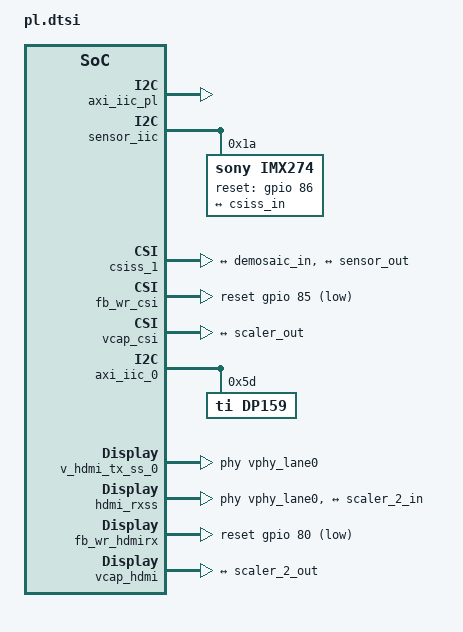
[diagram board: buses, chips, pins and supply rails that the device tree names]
/*
 * CAUTION: This file is automatically generated by Xilinx.
 * Version:  
 * Today is: Wed Nov  8 10:41:27 2017
 */


/ {
	amba_pl: amba_pl@0 {
		#address-cells = <2>;
		#size-cells = <2>;
		compatible = "simple-bus";
		ranges;
		
		psu_ctrl_ipi: PERIPHERAL@ff380000 {
			compatible = "xlnx,PERIPHERAL-1.0";
			reg = <0x0 0xff380000 0x0 0x80000>;
		};
		
		psu_message_buffers: PERIPHERAL@ff990000 {
			compatible = "xlnx,PERIPHERAL-1.0";
			reg = <0x0 0xff990000 0x0 0x10000>;
		};
		
		wl18xx_ctrl: gpio@a0002000 {
			#gpio-cells = <2>;
			compatible = "xlnx,xps-gpio-1.00.a";
			gpio-controller ;
			reg = <0x0 0xa0002000 0x0 0x1000>;
			xlnx,all-inputs = <0x0>;
			xlnx,all-inputs-2 = <0x0>;
			xlnx,all-outputs = <0x1>;
			xlnx,all-outputs-2 = <0x0>;
			xlnx,dout-default = <0x00000000>;
			xlnx,dout-default-2 = <0x00000000>;
			xlnx,gpio-width = <0x2>;
			xlnx,gpio2-width = <0x20>;
			xlnx,interrupt-present = <0x0>;
			xlnx,is-dual = <0x0>;
			xlnx,tri-default = <0xFFFFFFFF>;
			xlnx,tri-default-2 = <0xFFFFFFFF>;
		};
		
		misc_clk_0: misc_clk_0 {
			#clock-cells = <0>;
			clock-frequency = <50000000>;
			compatible = "fixed-clock";
		};
		
		misc_clk_1: misc_clk_1 {
			#clock-cells = <0>;
			clock-frequency = <300000000>;
			compatible = "fixed-clock";
		};
		
		axi_iic_pl: i2c@a0003000 {
			#address-cells = <1>;
			#size-cells = <0>;
			clocks = <&misc_clk_0>;
			compatible = "xlnx,xps-iic-2.00.a";
			interrupt-parent = <&axi_intc_0>;
			interrupts = <0 2>;
			reg = <0x0 0xa0003000 0x0 0x1000>;
		};
		
		axi_intc_0: interrupt-controller@a000a000 {
			#interrupt-cells = <2>;
			compatible = "xlnx,xps-intc-1.00.a";
			interrupt-controller ;
			interrupt-parent = <&gic>;
			interrupts = <0 89 4>;
			reg = <0x0 0xa000a000 0x0 0x1000>;
			xlnx,kind-of-intr = <0x0>;
			xlnx,num-intr-inputs = <0xa>;
		};
		
		/* MIPI CSI-2 SS */
		
		sensor_iic: i2c@a0080000 {
			#address-cells = <1>;
			#size-cells = <0>;
			clocks = <&misc_clk_0>;
			compatible = "xlnx,xps-iic-2.00.a";
			interrupt-parent = <&axi_intc_0>;
			interrupts = <9 2>;
			reg = <0x0 0xa0080000 0x0 0x10000>;
			
			imx274: sensor@1a {
				compatible = "sony,imx274";
				reg = <0x1a>;
				#address-cells = <1>;
				#size-cells = <0>;
				reset-gpios = <&gpio 86 0>;

				port@0 {
					reg = <0>;

					sensor_out: endpoint {
						remote-endpoint = <&csiss_in>;
					};
				};
			};
		};
		
		csiss_1: csiss@a0040000 {
			compatible = "xlnx,mipi-csi2-rx-subsystem-2.2", "xlnx,mipi-csi2-rx-subsystem-2.0", "xlnx,mipi-csi2-rx-subsystem";
			reg = <0x0 0xa0040000 0x0 0x10000>;
			clocks = <&misc_clk_1>;
			interrupt-parent = <&axi_intc_0>;
			interrupts = <7 2>;

			xlnx,max-lanes = <0x4>;
			xlnx,en-active-lanes;
			xlnx,vc = <0x4>;
			xlnx,csi-pxl-format = "RAW8";
			xlnx,vfb;
			xlnx,ppc = <0x4>;
			xlnx,axis-tdata-width = <0x20>;

			ports {
				#address-cells = <1>;
				#size-cells = <0>;

				port@0 {
					reg = <0>;

					xlnx,video-format = <12>;
					xlnx,video-width = <8>;
					xlnx,cfa-pattern = "rggb";

					csiss_out: endpoint {
						remote-endpoint = <&demosaic_in>;
					};
				};
				port@1 {
					reg = <1>;

					xlnx,video-format = <12>;
					xlnx,video-width = <8>;
					xlnx,cfa-pattern = "rggb";

					csiss_in: endpoint {
						data-lanes = <1 2 3 4>;
						remote-endpoint = <&sensor_out>;
					};
				};
			};
		};
		
		v_demosaic_0: v_demosaic@b0060000 {
			compatible = "xlnx,v-demosaic-v1.0", "xlnx,v-demosaic";
			reg = <0x0 0xb0060000 0x0 0x10000>;
			clocks = <&misc_clk_1>;

			reset-gpios = <&gpio 81 1>;

			ports {
				#address-cells = <1>;
				#size-cells = <0>;

				port@0 {
					reg = <0>;

					xlnx,video-width = <8>;
					xlnx,cfa-pattern = "rggb";

					demosaic_in: endpoint {
						remote-endpoint = <&csiss_out>;
					};
				};

				port@1 {
					reg = <1>;

					xlnx,video-width = <8>;

					demosaic_out: endpoint {
						remote-endpoint = <&gamma_in>;
					};
				};
			};
		};
		
		gamma_1: v_gamma@b0070000 {
			compatible = "xlnx,v-gamma-lut-1.0", "xlnx,v-gamma-lut-v1.0", "xlnx,v-gamma-lut";
			reg = <0x0 0xb0070000 0x0 0x10000>;
			clocks = <&misc_clk_1>;

			reset-gpios = <&gpio 82 1>;

			ports {
				#address-cells = <1>;
				#size-cells = <0>;

				port@0 {
					reg = <0>;

					xlnx,video-width = <8>;

					gamma_in: endpoint {
						remote-endpoint = <&demosaic_out>;
					};
				};

				port@1 {
					reg = <1>;

					xlnx,video-width = <8>;

					gamma_out: endpoint {
						remote-endpoint = <&csc_in>;
					};
				};
			};
		};
		
		csc_1: csc@b00e0000 {
			compatible = "xlnx,v-vpss-csc";
			reg = <0x0 0xb00e0000 0x0 0x10000>;
			clocks = <&misc_clk_1>;

			reset-gpios = <&gpio 83 1>;

			ports {
				#address-cells = <1>;
				#size-cells = <0>;

				port@0 {
					reg = <0>;

					xlnx,video-format = <2>;
					xlnx,video-width = <8>;

					csc_in: endpoint {
						remote-endpoint = <&gamma_out>;
					};
				};
				port@1 {
					reg = <1>;

					xlnx,video-format = <2>;
					xlnx,video-width = <8>;

					csc_out: endpoint {
						remote-endpoint = <&scaler_in>;
					};
				};
			};
		};
		
		scaler_1: scaler@b0100000 {
			compatible = "xlnx,v-vpss-scaler";
			reg = <0x0 0xb0100000 0x0 0x40000>;
			clocks = <&misc_clk_1>;

			xlnx,num-hori-taps = <8>;
			xlnx,num-vert-taps = <8>;
			xlnx,max-num-phases = <64>;
			xlnx,max-lines = <2160>;
			xlnx,max-pixels = <3840>;
			xlnx,pix-per-clk = <2>;

			reset-gpios = <&gpio 84 1>;

			ports {
				#address-cells = <1>;
				#size-cells = <0>;

				port@0 {
					reg = <0>;

					xlnx,video-format = <2>;
					xlnx,video-width = <8>;

					scaler_in: endpoint {
						remote-endpoint = <&csc_out>;
					};
				};
				port@1 {
					reg = <1>;

					xlnx,video-format = <0>;
					xlnx,video-width = <8>;

					scaler_out: endpoint {
						remote-endpoint = <&vcap_csi_in>;
					};
				};
			};
		};
		
		fb_wr_csi: fb_wr@b00f0000 {
			compatible = "xlnx,axi-frmbuf-wr-v2";
			reg = <0x0 0xb00f0000 0x0 0x10000>;
			#dma-cells = <1>;
			interrupt-parent = <&axi_intc_0>;
			interrupts = <8 2>;
			clocks = <&misc_clk_1>;
			clock-names = "axis";
			xlnx,vid-formats = "yuyv", "uyvy", "y8";
			reset-gpios = <&gpio 85 1>;
			xlnx,dma-addr-width = <64>;
		};
		
		vcap_csi {
			compatible = "xlnx,video";
			dmas = <&fb_wr_csi 0>;
			dma-names = "port0";

			ports {
				#address-cells = <1>;
				#size-cells = <0>;

				port@0 {
					reg = <0>;
					direction = "input";

					vcap_csi_in: endpoint {
						remote-endpoint = <&scaler_out>;
					};
				};
			};
		};
		
		/* HDMI-TX SS */
		
		axi_iic_0: i2c@a000b000 {
			#address-cells = <1>;
			#size-cells = <0>;
			clocks = <&misc_clk_0>;
			compatible = "xlnx,xps-iic-2.00.a";
			interrupt-parent = <&axi_intc_0>;
			interrupts = <4 2>;
			reg = <0x0 0xa000b000 0x0 0x1000>;
			
			dp159: hdmi-retimer@5d {
				status = "okay";
				compatible = "ti,dp159";
				reg = <0x5d>;
				#address-cells = <1>;
				#size-cells = <0>;
				#clock-cells = <0>;
			};
		};
		
		nidru: nidru {
			compatible = "fixed-clock";
			#clock-cells = <0x0>;
			clock-frequency = <156250000>;
		};
		
		v_hdmi_tx_ss_0: v_hdmi_tx_ss@a0020000 {
			compatible = "xlnx,v-hdmi-tx-ss-3.0";
			interrupt-parent = <&axi_intc_0>;
			interrupts = <2 2>;
			interrupt-names = "hdmitx";
			reg = <0x0 0xa0020000 0x0 0x20000>;
			reg-names = "hdmi-txss";
			clocks = <&misc_clk_0>, <&misc_clk_1>, <&dp159>;
			clock-names = "axi-lite", "video", "retimer-clk";
			phy-names = "hdmi-phy0", "hdmi-phy1", "hdmi-phy2";
			phys = <&vphy_lane0 0 1 1 1>, <&vphy_lane1 0 1 1 1>, <&vphy_lane2 0 1 1 1>;
			xlnx,addr-width = <0xa>;
			xlnx,exdes-nidru = "false";
			xlnx,exdes-rx-pll-selection = <0x0>;
			xlnx,exdes-topology = <0x1>;
			xlnx,exdes-tx-pll-selection = <0x6>;
			xlnx,hdmi-fast-switch = "false";
			xlnx,hdmi-version = <0x3>;
			xlnx,hpd-invert = "false";
			xlnx,hysteresis-level = <0xc>;
			xlnx,include-low-reso-vid = "false";
			xlnx,include-yuv420-sup = "true";
			xlnx,input-pixels-per-clock = <0x2>;
			xlnx,max-bits-per-component = <0x8>;
			xlnx,validation-enable = "false";
			xlnx,vid-interface = <0x0>;
			xlnx,video-mask-enable = <0x1>;
			xlnx,hdcp-authenticate = <0x0>;
			xlnx,hdcp-encrypt = <0x0>;
		};
		
		v_mix_0: v_mix@b0000000 {
			compatible = "xlnx,drm,video-mixer";
			interrupt-parent = <&axi_intc_0>;
			interrupts = <1 2>;
			reg = <0x0 0xb0000000 0x0 0x40000>;
			reset-gpios = <&gpio 79 1>;
			clocks = <&si570 0>;
			xlnx,encoder-slave = <&v_hdmi_tx_ss_0>;
			xlnx,connector-type = "HDMIA";
			xlnx,dma-addr-width=<32>;
			xlnx,bpc = <8>;
			xlnx,ppc = <2>;
			xlnx,num-layers = <5>;
			mixer_master_layer: layer_0 {
				xlnx,layer-id = <0>;
				xlnx,layer-width = <3840>;
				xlnx,layer-height = <2160>;
				xlnx,vformat = "bgr888";
			};
			mixer_overlay_1: layer_1 {
				xlnx,layer-id = <1>;
				xlnx,vformat = "yuyv";
				xlnx,layer-alpha;
			};
			mixer_overlay_2: layer_2 {
				xlnx,layer-id = <2>;
				xlnx,vformat = "yuyv";
				xlnx,layer-alpha;
			};
			mixer_overlay_3: layer_3 {
				xlnx,layer-id = <3>;
				xlnx,vformat = "uyvy";
				xlnx,layer-alpha;
			};
			mixer_overlay_4: layer_4 {
				xlnx,layer-id = <4>;
				xlnx,vformat = "argb8888";
				xlnx,layer-alpha;
				xlnx,layer-primary;
			};
		};
		
		vid_phy_controller_0: vid_phy_controller@a0060000 {
			compatible = "xlnx,vid-phy-controller-2.1";
			interrupt-parent = <&axi_intc_0>;
			interrupts = <3 2>;
			reg = <0x0 0xa0060000 0x0 0x10000>;
			
			clocks = <&misc_clk_0>, <&nidru>;
			clock-names = "axi-lite", "dru-clk";
			
			xlnx,axi4lite-enable = "true";
			xlnx,component-name = "tysom3_devel_vid_phy_controller_0_0";
			xlnx,device = "xczu7ev";
			xlnx,dru-refclk-fabric-buffer = "none";
			xlnx,err-irq-en = <0x0>;
			xlnx,hdmi-fast-switch = <0x1>;
			xlnx,input-pixels-per-clock = <0x2>;
			xlnx,int-hdmi-ver-cmptble = <0x3>;
			
			xlnx,nidru = <0x1>;
			xlnx,nidru-refclk-sel = <0x3>;
			
			xlnx,rx-gt-debug-ports = "false";
			xlnx,rx-no-of-channels = <0x3>;
			xlnx,rx-outclk-buffer = "none";
			xlnx,rx-pll-selection = <0x0>;
			
			xlnx,rx-protocol = <0x1>;
			xlnx,rx-refclk-sel = <0x1>;
			xlnx,rx-sb-ports = "true";
			xlnx,rx-tmds-clk-buffer = "bufg";
			xlnx,rx-video-clk-buffer = "bufg";
			
			xlnx,silicon-revision = <0x0>;
			xlnx,speedgrade = "-2";
			xlnx,supportlevel = <0x1>;
			xlnx,transceivercontrol = "false";
			xlnx,tx-gt-debug-ports = "false";
			xlnx,tx-no-of-channels = <0x3>;
			xlnx,tx-outclk-buffer = "none";
			xlnx,tx-pll-selection = <0x6>;
			xlnx,tx-protocol = <0x1>;
			xlnx,tx-refclk-fabric-buffer = "none";
			xlnx,tx-refclk-sel = <0x0>;
			xlnx,tx-sb-ports = "true";
			xlnx,tx-tmds-clk-buffer = "bufg";
			xlnx,tx-video-clk-buffer = "bufg";
			xlnx,txpi-port-en = "false";
			xlnx,txrefclk-rdy-invert = <0x1>;
			xlnx,use-oddr-for-tmds-clkout = "true";
			
			xlnx,vid-phy-axi4lite-addr-width = <0xa>;
			xlnx,vid-phy-axi4lite-data-width = <0x20>;
			xlnx,vid-phy-control-sb-rx-tdata-width = <0x1>;
			xlnx,vid-phy-control-sb-tx-tdata-width = <0x1>;
			xlnx,vid-phy-rx-axi4s-ch-int-tdata-width = <0x14>;
			xlnx,vid-phy-rx-axi4s-ch-tdata-width = <0x14>;
			xlnx,vid-phy-rx-axi4s-ch-tuser-width = <0x1>;
			xlnx,vid-phy-status-sb-rx-tdata-width = <0x2>;
			xlnx,vid-phy-status-sb-tx-tdata-width = <0x2>;
			xlnx,vid-phy-tx-axi4s-ch-int-tdata-width = <0x14>;
			xlnx,vid-phy-tx-axi4s-ch-tdata-width = <0x14>;
			xlnx,vid-phy-tx-axi4s-ch-tuser-width = <0x1>;
			xlnx,viper-reg = "false";
			
			xlnx,transceiver-type = <0x5>;
			xlnx,tx-buffer-bypass = <0x1>;
			xlnx,transceiver-width = <2>;
			
			vphy_lane0: vphy_lane@0 {
				#phy-cells = <4>;
			};
			vphy_lane1: vphy_lane@1 {
				#phy-cells = <4>;
			};
			vphy_lane2: vphy_lane@2 {
				#phy-cells = <4>;
			};
			vphy_lane3: vphy_lane@3 {
				#phy-cells = <4>;
			};
		};
		
		/* HDMI-RX SS */
		
		hdmi_rxss: hdmi_rxss@a0010000 {
			compatible = "xlnx,v-hdmi-rx-ss-3.0", "xlnx,v-hdmi-rx-ss-2.0";
			reg = <0x0 0xa0010000 0x0 0x10000>;
			
			interrupt-parent = <&axi_intc_0>;
			interrupts = <5 2>;
			interrupt-names = "hdmirx";
			
			clocks = <&misc_clk_0>, <&misc_clk_1>;
			clock-names = "axi-lite", "video";
			
			phy-names = "hdmi-phy0", "hdmi-phy1", "hdmi-phy2";
			phys = <&vphy_lane0 0 1 1 0>, <&vphy_lane1 0 1 1 0>, <&vphy_lane2 0 1 1 0>;

			xlnx,input-pixels-per-clock = <2>;
			xlnx,max-bits-per-component = <8>;
			xlnx,hdmi-rx-offset = <0x00000>;
			
			xlnx,edid-ram-size = <0x100>;

			ports {
				#address-cells = <1>;
				#size-cells = <0>;

				port@0 {
					reg = <0>;

					xlnx,video-format = <2>;
					xlnx,video-width = <8>;

					hdmi_rxss_out: endpoint {
						remote-endpoint = <&scaler_2_in>;
					};
				};
			};
		};
		
		scaler_2: scaler@b0080000 {
			compatible = "xlnx,v-vpss-scaler";
			reg = <0x0 0xb0080000 0x0 0x40000>;
			clocks = <&misc_clk_1>;

			xlnx,num-hori-taps = <8>;
			xlnx,num-vert-taps = <8>;
			xlnx,max-num-phases = <64>;
			xlnx,max-lines = <2160>;
			xlnx,max-pixels = <3840>;
			xlnx,pix-per-clk = <2>;

			reset-gpios = <&gpio 78 1>;

			ports {
				#address-cells = <1>;
				#size-cells = <0>;

				port@0 {
					reg = <0>;

					xlnx,video-format = <2>;
					xlnx,video-width = <8>;

					scaler_2_in: endpoint {
						remote-endpoint = <&hdmi_rxss_out>;
					};
				};
				port@1 {
					reg = <1>;

					xlnx,video-format = <0>;
					xlnx,video-width = <8>;

					scaler_2_out: endpoint {
						remote-endpoint = <&vcap_hdmi_in>;
					};
				};
			};
		};
		
		fb_wr_hdmirx: fb_wr@b0050000 {
			compatible = "xlnx,axi-frmbuf-wr-v2";
			reg = <0x0 0xb0050000 0x0 0x10000>;
			#dma-cells = <1>;
			
			interrupt-parent = <&axi_intc_0>;
			interrupts = <6 2>;
			
			clocks = <&misc_clk_1>;
			clock-names = "axis";
			reset-gpios = <&gpio 80 1>;
			xlnx,dma-addr-width = <64>;
			xlnx,vid-formats = "yuyv", "uyvy", "y8";
		};
		
		vcap_hdmi {
			compatible = "xlnx,video";
			dmas = <&fb_wr_hdmirx 0>;
			dma-names = "port0";

			ports {
				#address-cells = <1>;
				#size-cells = <0>;

				port@0 {
					reg = <0>;
					direction = "input";
					vcap_hdmi_in: endpoint {
						remote-endpoint = <&scaler_2_out>;
					};
				};
			};
		};
	};
};
